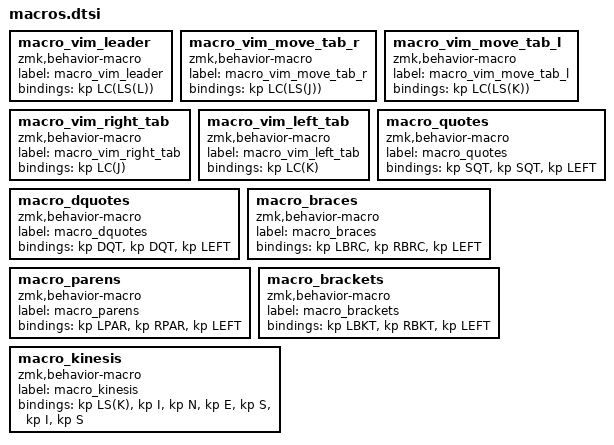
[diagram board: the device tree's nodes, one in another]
macro_vim_leader: macro_vim_leader{
compatible = "zmk,behavior-macro";
label = "macro_vim_leader";
#binding-cells = <0>;
bindings = <&kp LC(LS(L))>;
};
macro_vim_move_tab_r: macro_vim_move_tab_r{
compatible = "zmk,behavior-macro";
label = "macro_vim_move_tab_r";
#binding-cells = <0>;
bindings = <&kp LC(LS(J))>;
};
macro_vim_move_tab_l: macro_vim_move_tab_l{
compatible = "zmk,behavior-macro";
label = "macro_vim_move_tab_l";
#binding-cells = <0>;
bindings = <&kp LC(LS(K))>;
};
macro_vim_right_tab: macro_vim_right_tab{
compatible = "zmk,behavior-macro";
label = "macro_vim_right_tab";
#binding-cells = <0>;
bindings = <&kp LC(J)>;
};
macro_vim_left_tab: macro_vim_left_tab{
compatible = "zmk,behavior-macro";
label = "macro_vim_left_tab";
#binding-cells = <0>;
bindings = <&kp LC(K)>;
};
macro_quotes: macro_quotes{
compatible = "zmk,behavior-macro";
label = "macro_quotes";
#binding-cells = <0>;
bindings = <&kp SQT>, <&kp SQT>, <&kp LEFT>;
};
macro_dquotes: macro_dquotes{
compatible = "zmk,behavior-macro";
label = "macro_dquotes";
#binding-cells = <0>;
bindings = <&kp DQT>, <&kp DQT>, <&kp LEFT>;
};
macro_braces: macro_braces{
compatible = "zmk,behavior-macro";
label = "macro_braces";
#binding-cells = <0>;
bindings = <&kp LBRC>, <&kp RBRC>, <&kp LEFT>;
};
macro_parens: macro_parens{
compatible = "zmk,behavior-macro";
label = "macro_parens";
#binding-cells = <0>;
bindings = <&kp LPAR>, <&kp RPAR>, <&kp LEFT>;
};
macro_brackets: macro_brackets{
compatible = "zmk,behavior-macro";
label = "macro_brackets";
#binding-cells = <0>;
bindings = <&kp LBKT>, <&kp RBKT>, <&kp LEFT>;
};
macro_kinesis: macro_kinesis{
compatible = "zmk,behavior-macro";
label = "macro_kinesis";
#binding-cells = <0>;
bindings = <&kp LS(K)>, <&kp I>, <&kp N>, <&kp E>, <&kp S>, <&kp I>, <&kp S>;
};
